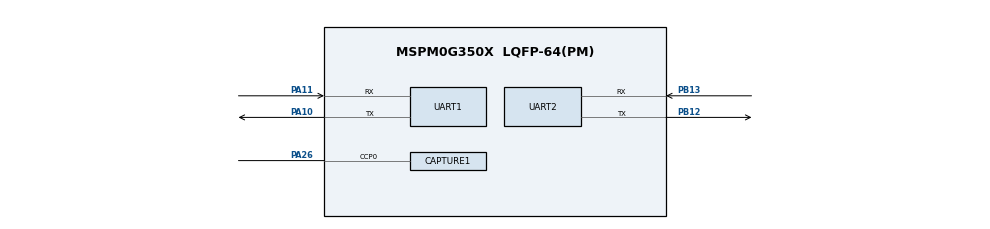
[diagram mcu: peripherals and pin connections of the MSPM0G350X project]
/**
 * @cliArgs --device "MSPM0G350X" --package "LQFP-64(PM)" --part "Default" --product "mspm0_sdk@1.30.00.03"
 * @versions {"tool":"1.20.0+3587"}
 */

/**
 * Import the modules used in this configuration.
 */
const ADC12         = scripting.addModule("/ti/driverlib/ADC12", {}, false);
const ADC121        = ADC12.addInstance();
const ADC122        = ADC12.addInstance();
const CAPTURE       = scripting.addModule("/ti/driverlib/CAPTURE", {}, false);
const CAPTURE1      = CAPTURE.addInstance();
const SYSCTL        = scripting.addModule("/ti/driverlib/SYSCTL");
const TIMER         = scripting.addModule("/ti/driverlib/TIMER", {}, false);
const TIMER1        = TIMER.addInstance();
const TIMER2        = TIMER.addInstance();
const TIMER3        = TIMER.addInstance();
const TIMER4        = TIMER.addInstance();
const UART          = scripting.addModule("/ti/driverlib/UART", {}, false);
const UART1         = UART.addInstance();
const UART2         = UART.addInstance();
const ProjectConfig = scripting.addModule("/ti/project_config/ProjectConfig");

/**
 * Write custom configuration values to the imported modules.
 */
const divider9       = system.clockTree["UDIV"];
divider9.divideValue = 2;

const multiplier2         = system.clockTree["PLL_QDIV"];
multiplier2.multiplyValue = 4;

const mux4       = system.clockTree["EXHFMUX"];
mux4.inputSelect = "EXHFMUX_XTAL";

const mux8       = system.clockTree["HSCLKMUX"];
mux8.inputSelect = "HSCLKMUX_SYSPLL0";

const mux12       = system.clockTree["SYSPLLMUX"];
mux12.inputSelect = "zSYSPLLMUX_HFCLK";

const pinFunction4        = system.clockTree["HFXT"];
pinFunction4.inputFreq    = 40;
pinFunction4.enable       = true;
pinFunction4.HFXTStartup  = 10;
pinFunction4.HFCLKMonitor = true;

ADC121.$name                             = "ADC12_0";
ADC121.repeatMode                        = true;
ADC121.trigSrc                           = "DL_ADC12_TRIG_SRC_EVENT";
ADC121.adcMem0trig                       = "DL_ADC12_TRIGGER_MODE_TRIGGER_NEXT";
ADC121.powerDownMode                     = "DL_ADC12_POWER_DOWN_MODE_MANUAL";
ADC121.sampleTime0                       = "62.5ns";
ADC121.enabledInterrupts                 = ["DL_ADC12_INTERRUPT_DMA_DONE"];
ADC121.configureDMA                      = true;
ADC121.sampCnt                           = 1;
ADC121.enabledDMATriggers                = ["DL_ADC12_DMA_MEM0_RESULT_LOADED"];
ADC121.subChanID                         = 1;
ADC121.adcPin0Config.$name               = "ti_driverlib_gpio_GPIOPinGeneric1";
ADC121.DMA_CHANNEL.$name                 = "DMA_CH0";
ADC121.DMA_CHANNEL.addressMode           = "f2b";
ADC121.DMA_CHANNEL.srcLength             = "HALF_WORD";
ADC121.DMA_CHANNEL.dstLength             = "HALF_WORD";
ADC121.DMA_CHANNEL.configureTransferSize = true;
ADC121.DMA_CHANNEL.transferSize          = 1024;
ADC121.DMA_CHANNEL.transferMode          = "FULL_CH_REPEAT_SINGLE";

ADC122.$name                             = "ADC12_1";
ADC122.repeatMode                        = true;
ADC122.trigSrc                           = "DL_ADC12_TRIG_SRC_EVENT";
ADC122.adcMem0trig                       = "DL_ADC12_TRIGGER_MODE_TRIGGER_NEXT";
ADC122.powerDownMode                     = "DL_ADC12_POWER_DOWN_MODE_MANUAL";
ADC122.sampleTime0                       = "62.5ns";
ADC122.configureDMA                      = true;
ADC122.enabledInterrupts                 = ["DL_ADC12_INTERRUPT_DMA_DONE"];
ADC122.interruptPriority                 = "1";
ADC122.sampCnt                           = 1;
ADC122.enabledDMATriggers                = ["DL_ADC12_DMA_MEM0_RESULT_LOADED"];
ADC122.subChanID                         = 2;
ADC122.adcPin0Config.$name               = "ti_driverlib_gpio_GPIOPinGeneric4";
ADC122.DMA_CHANNEL.$name                 = "DMA_CH1";
ADC122.DMA_CHANNEL.addressMode           = "f2b";
ADC122.DMA_CHANNEL.srcLength             = "HALF_WORD";
ADC122.DMA_CHANNEL.dstLength             = "HALF_WORD";
ADC122.DMA_CHANNEL.configureTransferSize = true;
ADC122.DMA_CHANNEL.transferSize          = 1024;
ADC122.DMA_CHANNEL.transferMode          = "FULL_CH_REPEAT_SINGLE";

const Board = scripting.addModule("/ti/driverlib/Board", {}, false);

CAPTURE1.$name                      = "CAPTURE_0";
CAPTURE1.captMode                   = "COMBINED";
CAPTURE1.interrupts                 = ["CC1_DN"];
CAPTURE1.timerPeriod                = "0";
CAPTURE1.peripheral.$assign         = "TIMG7";
CAPTURE1.peripheral.ccp0Pin.$assign = "PA26";
CAPTURE1.ccp0PinConfig.$name        = "ti_driverlib_gpio_GPIOPinGeneric0";

SYSCTL.forceDefaultClkConfig = true;
SYSCTL.clockTreeEn           = true;
SYSCTL.validateClkStatus     = true;

TIMER1.$name              = "TIMER_0";
TIMER1.timerClkDiv        = 8;
TIMER1.timerClkPrescale   = 256;
TIMER1.timerPeriod        = "3 s";
TIMER1.peripheral.$assign = "TIMG0";

TIMER2.$name            = "TIMER_1";
TIMER2.timerClkDiv      = 8;
TIMER2.timerClkPrescale = 256;
TIMER2.interrupts       = ["ZERO"];
TIMER2.timerPeriod      = "1 s";

TIMER3.$name                       = "TIMER_ADC0";
TIMER3.timerMode                   = "PERIODIC";
TIMER3.timerPeriod                 = "1us";
TIMER3.event1PublisherChannel      = 1;
TIMER3.event1ControllerInterruptEn = ["ZERO_EVENT"];
TIMER3.timerClkDiv                 = 5;

TIMER4.$name                       = "TIMER_ADC1";
TIMER4.timerMode                   = "PERIODIC";
TIMER4.event1ControllerInterruptEn = ["ZERO_EVENT"];
TIMER4.event2PublisherChannel      = 2;
TIMER4.event2ControllerInterruptEn = ["ZERO_EVENT"];
TIMER4.timerClkDiv                 = 8;
TIMER4.timerClkPrescale            = 5;
TIMER4.timerPeriod                 = "50 us";

UART1.$name                            = "UART_LCD";
UART1.targetBaudRate                   = 115200;
UART1.enabledInterrupts                = ["RX"];
UART1.interruptPriority                = "0";
UART1.peripheral.rxPin.$assign         = "PA11";
UART1.peripheral.txPin.$assign         = "PA10";
UART1.txPinConfig.direction            = scripting.forceWrite("OUTPUT");
UART1.txPinConfig.hideOutputInversion  = scripting.forceWrite(false);
UART1.txPinConfig.onlyInternalResistor = scripting.forceWrite(false);
UART1.txPinConfig.passedPeripheralType = scripting.forceWrite("Digital");
UART1.txPinConfig.$name                = "ti_driverlib_gpio_GPIOPinGeneric2";
UART1.rxPinConfig.hideOutputInversion  = scripting.forceWrite(false);
UART1.rxPinConfig.onlyInternalResistor = scripting.forceWrite(false);
UART1.rxPinConfig.passedPeripheralType = scripting.forceWrite("Digital");
UART1.rxPinConfig.$name                = "ti_driverlib_gpio_GPIOPinGeneric3";

UART2.$name                            = "UART_BT";
UART2.targetBaudRate                   = 115200;
UART2.peripheral.rxPin.$assign         = "PB13";
UART2.peripheral.txPin.$assign         = "PB12";
UART2.txPinConfig.$name                = "ti_driverlib_gpio_GPIOPinGeneric5";
UART2.txPinConfig.direction            = scripting.forceWrite("OUTPUT");
UART2.txPinConfig.hideOutputInversion  = scripting.forceWrite(false);
UART2.txPinConfig.onlyInternalResistor = scripting.forceWrite(false);
UART2.txPinConfig.passedPeripheralType = scripting.forceWrite("Digital");
UART2.rxPinConfig.$name                = "ti_driverlib_gpio_GPIOPinGeneric6";
UART2.rxPinConfig.hideOutputInversion  = scripting.forceWrite(false);
UART2.rxPinConfig.onlyInternalResistor = scripting.forceWrite(false);
UART2.rxPinConfig.passedPeripheralType = scripting.forceWrite("Digital");

ProjectConfig.genLibCMSIS = true;

/**
 * Pinmux solution for unlocked pins/peripherals. This ensures that minor changes to the automatic solver in a future
 * version of the tool will not impact the pinmux you originally saw.  These lines can be completely deleted in order to
 * re-solve from scratch.
 */
pinFunction4.peripheral.$suggestSolution           = "SYSCTL";
pinFunction4.peripheral.hfxInPin.$suggestSolution  = "PA5";
pinFunction4.peripheral.hfxOutPin.$suggestSolution = "PA6";
ADC121.peripheral.$suggestSolution                 = "ADC1";
ADC121.peripheral.adcPin0.$suggestSolution         = "PA15";
ADC121.DMA_CHANNEL.peripheral.$suggestSolution     = "DMA_CH1";
ADC122.peripheral.$suggestSolution                 = "ADC0";
ADC122.peripheral.adcPin0.$suggestSolution         = "PA27";
ADC122.DMA_CHANNEL.peripheral.$suggestSolution     = "DMA_CH0";
Board.peripheral.$suggestSolution                  = "DEBUGSS";
Board.peripheral.swclkPin.$suggestSolution         = "PA20";
Board.peripheral.swdioPin.$suggestSolution         = "PA19";
TIMER2.peripheral.$suggestSolution                 = "TIMG6";
TIMER3.peripheral.$suggestSolution                 = "TIMA1";
TIMER4.peripheral.$suggestSolution                 = "TIMA0";
UART1.peripheral.$suggestSolution                  = "UART0";
UART2.peripheral.$suggestSolution                  = "UART3";
